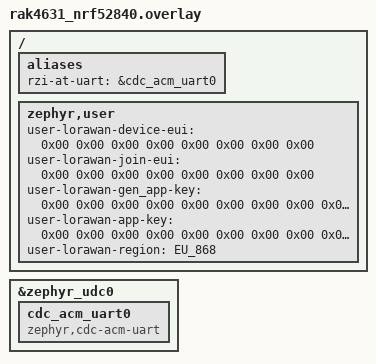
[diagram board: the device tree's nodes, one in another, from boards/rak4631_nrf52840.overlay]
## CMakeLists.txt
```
# SPDX-License-Identifier: Apache-2.0

cmake_minimum_required(VERSION 3.20.0)

find_package(Zephyr REQUIRED HINTS $ENV{ZEPHYR_BASE})
project(rzi_lorawan_at)

target_sources(app PRIVATE src/main.c)
```

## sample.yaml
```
# SPDX-License-Identifier: Apache-2.0
sample:
  name: RZI LoRaWAN AT
  description: >
    RAK RUI3-compatible AT command interface over USB CDC UART,
    built on the RZI LoRaWAN service
tests:
  sample.rzi.lorawan.at:
    sysbuild: true
    build_only: true
    tags:
      - rzi
      - lorawan
      - at
    platform_allow:
      - rzi_rak4631/nrf52840
    integration_platforms:
      - rzi_rak4631/nrf52840
```

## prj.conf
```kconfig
# SPDX-License-Identifier: Apache-2.0
CONFIG_GPIO=y
CONFIG_SPI=y
CONFIG_FLASH=y
CONFIG_PM_DEVICE=y
CONFIG_TEST_RANDOM_GENERATOR=y
CONFIG_HEAP_MEM_POOL_SIZE=8192

# The AT service owns the serial port: keep logs and console off it.
CONFIG_LOG=n
CONFIG_CONSOLE=n
CONFIG_UART_CONSOLE=n

# USB CDC ACM serial port used for AT commands.
CONFIG_SERIAL=y
CONFIG_UART_LINE_CTRL=y
CONFIG_USB_DEVICE_STACK_NEXT=y
CONFIG_CDC_ACM_SERIAL_INITIALIZE_AT_BOOT=y

# Zephyr LoRaWAN subsystems stay disabled; RZI uses the USP/LBM backend.
CONFIG_LORA=n
CONFIG_LORAWAN=n

CONFIG_RZI=y
CONFIG_RZI_LORAWAN=y
CONFIG_RZI_AT=y
CONFIG_RZI_AT_COMMAND_LORAWAN=y
CONFIG_RZI_LORA=y
CONFIG_RZI_AT_COMMAND_LORA=y
CONFIG_RZI_AT_ADAPTER_UART=y
CONFIG_RZI_AT_NVM=y
# Settings backend choice (cannot be selected by the module).
CONFIG_SETTINGS_NVS=y

CONFIG_RZI_MCUBOOT=y
CONFIG_STREAM_FLASH=y
CONFIG_IMG_MANAGER=y
CONFIG_LORA_BASICS_MODEM_DRIVERS_EVENT_TRIGGER_NO_THREAD=y
```

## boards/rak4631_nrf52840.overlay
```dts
/* SPDX-License-Identifier: Apache-2.0 */

#include "rak4631_usp_compat.dtsi"

/ {
	aliases {
		/* Keep the AT UART adapter independent from the system console. */
		rzi-at-uart = &cdc_acm_uart0;
	};

	zephyr,user {
		/* Default credentials; change them at runtime with
		 * AT+DEVEUI, AT+APPEUI and AT+APPKEY before AT+JOIN.
		 */
		user-lorawan-device-eui = <0x00 0x00 0x00 0x00 0x00 0x00 0x00 0x00>;
		user-lorawan-join-eui = <0x00 0x00 0x00 0x00 0x00 0x00 0x00 0x00>;
		user-lorawan-gen_app-key = <0x00 0x00 0x00 0x00 0x00 0x00 0x00 0x00
					    0x00 0x00 0x00 0x00 0x00 0x00 0x00 0x00>;
		user-lorawan-app-key = <0x00 0x00 0x00 0x00 0x00 0x00 0x00 0x00
					0x00 0x00 0x00 0x00 0x00 0x00 0x00 0x00>;
		user-lorawan-region = "EU_868";
	};
};

/* Standard Zephyr USB CDC serial port. */
&zephyr_udc0 {
	cdc_acm_uart0: cdc_acm_uart0 {
		compatible = "zephyr,cdc-acm-uart";
	};
};
```

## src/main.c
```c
/* SPDX-License-Identifier: Apache-2.0 */

#include <errno.h>
#include <zephyr/device.h>
#include <zephyr/devicetree.h>
#include <zephyr/drivers/uart.h>
#include <zephyr/kernel.h>
#include <rzi/at/uart.h>

#define AT_UART_NODE DT_ALIAS(rzi_at_uart)

#if !DT_NODE_EXISTS(AT_UART_NODE)
#error "The board overlay must define the rzi-at-uart alias"
#endif

static const struct device *const at_uart = DEVICE_DT_GET(AT_UART_NODE);

int main(void)
{
	if (!device_is_ready(at_uart)) {
		return -ENODEV;
	}

	/* Give a USB CDC host time to open the port before the service
	 * starts; on a plain UART this returns immediately.
	 */
	if (DT_NODE_HAS_COMPAT(AT_UART_NODE, zephyr_cdc_acm_uart)) {
		uint32_t dtr = 0;

		for (int i = 0; i < 100 && dtr == 0; i++) {
			(void)uart_line_ctrl_get(at_uart, UART_LINE_CTRL_DTR, &dtr);
			k_msleep(100);
		}
	}

	/* The AT service owns the UART from here on. */
	return rzi_at_uart_start(at_uart);
}
```

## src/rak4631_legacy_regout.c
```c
/* SPDX-License-Identifier: Apache-2.0 */
/* Sample-only board compatibility for the currently pinned Zephyr BSP. */

#include <zephyr/init.h>
#include <hal/nrf_power.h>

void board_early_init_hook(void)
{
	if ((nrf_power_mainregstatus_get(NRF_POWER) == NRF_POWER_MAINREGSTATUS_HIGH) &&
	    ((NRF_UICR->REGOUT0 & UICR_REGOUT0_VOUT_Msk) ==
	     (UICR_REGOUT0_VOUT_DEFAULT << UICR_REGOUT0_VOUT_Pos))) {
		NRF_NVMC->CONFIG = NVMC_CONFIG_WEN_Wen << NVMC_CONFIG_WEN_Pos;
		while (NRF_NVMC->READY == NVMC_READY_READY_Busy) {
			;
		}

		NRF_UICR->REGOUT0 = (NRF_UICR->REGOUT0 & ~((uint32_t)UICR_REGOUT0_VOUT_Msk)) |
				    (UICR_REGOUT0_VOUT_3V3 << UICR_REGOUT0_VOUT_Pos);
		NRF_NVMC->CONFIG = NVMC_CONFIG_WEN_Ren << NVMC_CONFIG_WEN_Pos;
		while (NRF_NVMC->READY == NVMC_READY_READY_Busy) {
			;
		}

		NVIC_SystemReset();
	}
}
```
